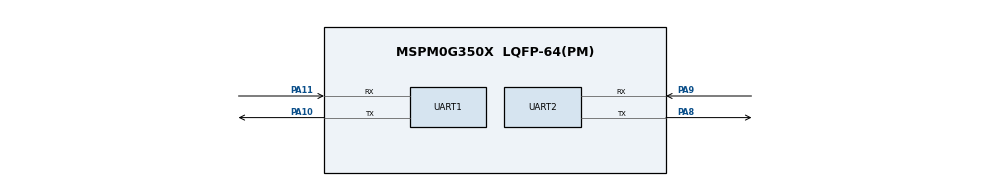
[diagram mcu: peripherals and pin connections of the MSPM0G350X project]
/**
 * @cliArgs --device "MSPM0G350X" --part "Default" --package "LQFP-64(PM)" --product "mspm0_sdk@2.05.01.00"
 * @versions {"tool":"1.24.0+4110"}
 */

/**
 * Import the modules used in this configuration.
 */
const ADC12  = scripting.addModule("/ti/driverlib/ADC12", {}, false);
const ADC121 = ADC12.addInstance();
const GPIO   = scripting.addModule("/ti/driverlib/GPIO", {}, false);
const GPIO1  = GPIO.addInstance();
const SYSCTL = scripting.addModule("/ti/driverlib/SYSCTL");
const TIMER  = scripting.addModule("/ti/driverlib/TIMER", {}, false);
const TIMER1 = TIMER.addInstance();
const UART   = scripting.addModule("/ti/driverlib/UART", {}, false);
const UART1  = UART.addInstance();
const UART2  = UART.addInstance();

/**
 * Write custom configuration values to the imported modules.
 */
ADC121.$name                      = "ADC12_0";
ADC121.repeatMode                 = true;
ADC121.trigSrc                    = "DL_ADC12_TRIG_SRC_EVENT";
ADC121.adcMem0chansel             = "DL_ADC12_INPUT_CHAN_2";
ADC121.enableFIFO                 = true;
ADC121.configureDMA               = true;
ADC121.powerDownMode              = "DL_ADC12_POWER_DOWN_MODE_MANUAL";
ADC121.subChanID                  = 1;
ADC121.sampCnt                    = 6;
ADC121.sampleTime0                = "62.5ns";
ADC121.enabledInterrupts          = ["DL_ADC12_INTERRUPT_DMA_DONE"];
ADC121.enabledDMATriggers         = ["DL_ADC12_DMA_MEM10_RESULT_LOADED"];
ADC121.peripheral.adcPin2.$assign = "PA25";
ADC121.adcPin2Config.$name        = "ti_driverlib_gpio_GPIOPinGeneric2";
ADC121.DMA_CHANNEL.$name          = "DMA_CH0";
ADC121.DMA_CHANNEL.addressMode    = "f2b";

const Board = scripting.addModule("/ti/driverlib/Board", {}, false);

GPIO1.$name                          = "GPIO_GRP_0";
GPIO1.associatedPins[0].$name        = "PIN_0";
GPIO1.associatedPins[0].assignedPort = "PORTB";
GPIO1.associatedPins[0].assignedPin  = "14";

SYSCTL.forceDefaultClkConfig = true;

TIMER1.$name                       = "TIMER_0";
TIMER1.timerPeriod                 = "0.0005 ms";
TIMER1.event1PublisherChannel      = 1;
TIMER1.event1ControllerInterruptEn = ["ZERO_EVENT"];
TIMER1.timerMode                   = "PERIODIC";
TIMER1.peripheral.$assign          = "TIMG0";

UART1.$name                    = "UART_0";
UART1.targetBaudRate           = 115200;
UART1.enabledInterrupts        = ["RX"];
UART1.peripheral.rxPin.$assign = "PA11";
UART1.peripheral.txPin.$assign = "PA10";
UART1.txPinConfig.$name        = "ti_driverlib_gpio_GPIOPinGeneric0";
UART1.rxPinConfig.$name        = "ti_driverlib_gpio_GPIOPinGeneric1";

UART2.$name                    = "UART_1";
UART2.peripheral.$assign       = "UART1";
UART2.peripheral.rxPin.$assign = "PA9";
UART2.peripheral.txPin.$assign = "PA8";
UART2.txPinConfig.$name        = "ti_driverlib_gpio_GPIOPinGeneric3";
UART2.rxPinConfig.$name        = "ti_driverlib_gpio_GPIOPinGeneric4";

/**
 * Pinmux solution for unlocked pins/peripherals. This ensures that minor changes to the automatic solver in a future
 * version of the tool will not impact the pinmux you originally saw.  These lines can be completely deleted in order to
 * re-solve from scratch.
 */
ADC121.peripheral.$suggestSolution             = "ADC0";
ADC121.DMA_CHANNEL.peripheral.$suggestSolution = "DMA_CH0";
Board.peripheral.$suggestSolution              = "DEBUGSS";
Board.peripheral.swclkPin.$suggestSolution     = "PA20";
Board.peripheral.swdioPin.$suggestSolution     = "PA19";
GPIO1.associatedPins[0].pin.$suggestSolution   = "PB14";
SYSCTL.peripheral.$suggestSolution             = "SYSCTL";
UART1.peripheral.$suggestSolution              = "UART0";
